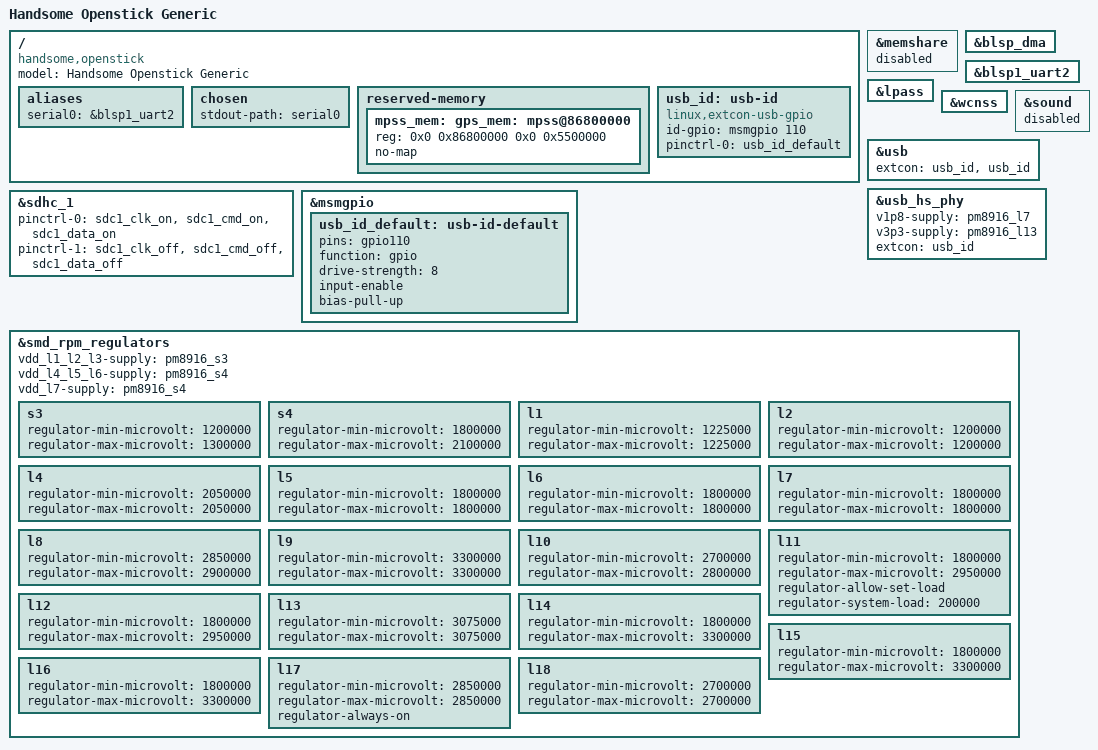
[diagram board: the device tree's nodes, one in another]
// SPDX-License-Identifier: GPL-2.0-only
/*
 * Copyright (C) 2021-2022 HandsomeYingyan <handsomeyingyan@gmail.com>
 *
 */

/dts-v1/;

#include "msm8916-pm8916.dtsi"
#include "msm8916-modem.dtsi"
#include <dt-bindings/gpio/gpio.h>
#include <dt-bindings/input/input.h>
#include <dt-bindings/pinctrl/qcom,pmic-gpio.h>
#include <dt-bindings/pinctrl/qcom,pmic-mpp.h>
#include <dt-bindings/sound/apq8016-lpass.h>


/ {
	model = "Handsome Openstick Generic";
	compatible = "handsome,openstick", "qcom,msm8916";

	aliases {
		serial0 = &blsp1_uart2;
	};

	chosen {
		stdout-path = "serial0";
	};

	reserved-memory {
		mpss_mem: gps_mem: mpss@86800000 {
			reg = <0x0 0x86800000 0x0 0x5500000>;
			no-map;
		};
	};

	usb_id: usb-id {
		compatible = "linux,extcon-usb-gpio";
		id-gpio = <&msmgpio 110 GPIO_ACTIVE_HIGH>;
		pinctrl-names = "default";
		pinctrl-0 = <&usb_id_default>;
	};

};

/*
 * The modem firmware sends a "query_size" memshare request for client ID 1,
 * but basically does not do anything with it. GPS works only if:
 *   - Memshare is not present or
 *   - Memshare replies to the request with an error
 * Overall it seems pointless to enable memshare for this device.
 */
 
&memshare {
	status = "disabled";
};

&blsp_dma {
	status = "okay";
};

&blsp1_uart2 {
	status = "okay";
};

&lpass {
	status = "okay";
};

&wcnss {
	status = "okay";
};

&sdhc_1 {
	status = "okay";

	pinctrl-names = "default", "sleep";
	pinctrl-0 = <&sdc1_clk_on &sdc1_cmd_on &sdc1_data_on>;
	pinctrl-1 = <&sdc1_clk_off &sdc1_cmd_off &sdc1_data_off>;
};

&sound {
	status = "disabled";
};

&usb {
	status = "okay";
	extcon = <&usb_id>, <&usb_id>;
};

&usb_hs_phy {
	v1p8-supply = <&pm8916_l7>;
	v3p3-supply = <&pm8916_l13>;
	extcon = <&usb_id>;
};

&msmgpio {
	usb_id_default: usb-id-default {
		pins = "gpio110";
		function = "gpio";

		drive-strength = <8>;
		input-enable;
		bias-pull-up;
	};
};

&smd_rpm_regulators {
	vdd_l1_l2_l3-supply = <&pm8916_s3>;
	vdd_l4_l5_l6-supply = <&pm8916_s4>;
	vdd_l7-supply = <&pm8916_s4>;

	s3 {
		regulator-min-microvolt = <1200000>;
		regulator-max-microvolt = <1300000>;
	};

	s4 {
		regulator-min-microvolt = <1800000>;
		regulator-max-microvolt = <2100000>;
	};

	l1 {
		regulator-min-microvolt = <1225000>;
		regulator-max-microvolt = <1225000>;
	};

	l2 {
		regulator-min-microvolt = <1200000>;
		regulator-max-microvolt = <1200000>;
	};

	l4 {
		regulator-min-microvolt = <2050000>;
		regulator-max-microvolt = <2050000>;
	};

	l5 {
		regulator-min-microvolt = <1800000>;
		regulator-max-microvolt = <1800000>;
	};

	l6 {
		regulator-min-microvolt = <1800000>;
		regulator-max-microvolt = <1800000>;
	};

	l7 {
		regulator-min-microvolt = <1800000>;
		regulator-max-microvolt = <1800000>;
	};

	l8 {
		regulator-min-microvolt = <2850000>;
		regulator-max-microvolt = <2900000>;
	};

	l9 {
		regulator-min-microvolt = <3300000>;
		regulator-max-microvolt = <3300000>;
	};

	l10 {
		regulator-min-microvolt = <2700000>;
		regulator-max-microvolt = <2800000>;
	};

	l11 {
		regulator-min-microvolt = <1800000>;
		regulator-max-microvolt = <2950000>;
		regulator-allow-set-load;
		regulator-system-load = <200000>;
	};

	l12 {
		regulator-min-microvolt = <1800000>;
		regulator-max-microvolt = <2950000>;
	};

	l13 {
		regulator-min-microvolt = <3075000>;
		regulator-max-microvolt = <3075000>;
	};

	l14 {
		regulator-min-microvolt = <1800000>;
		regulator-max-microvolt = <3300000>;
	};

	l15 {
		regulator-min-microvolt = <1800000>;
		regulator-max-microvolt = <3300000>;
	};

	l16 {
		regulator-min-microvolt = <1800000>;
		regulator-max-microvolt = <3300000>;
	};

	l17 {
		regulator-min-microvolt = <2850000>;
		regulator-max-microvolt = <2850000>;
		regulator-always-on;
	};

	l18 {
		regulator-min-microvolt = <2700000>;
		regulator-max-microvolt = <2700000>;
	};
};
